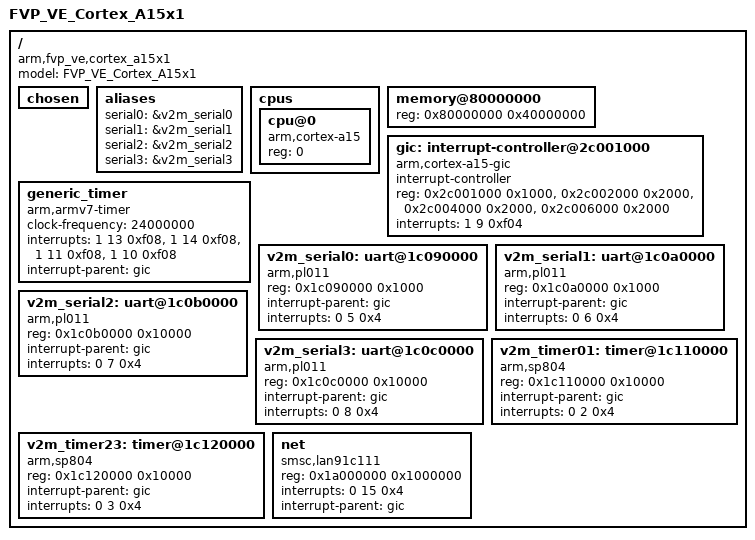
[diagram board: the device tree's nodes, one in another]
/*
 * ARM Ltd. Fast Models
 *
 * Versatile Express (VE) system model
 * ARMCortexA15x1CT
 *
 * RTSM_VE_Cortex_A15x1.lisa
 */

/dts-v1/;

/ {
	model = "FVP_VE_Cortex_A15x1";
	compatible = "arm,fvp_ve,cortex_a15x1";
	#address-cells = <1>;
	#size-cells = <1>;

	chosen { };

	aliases {
		serial0 = &v2m_serial0;
		serial1 = &v2m_serial1;
		serial2 = &v2m_serial2;
		serial3 = &v2m_serial3;
	};

	cpus {
		#address-cells = <1>;
		#size-cells = <0>;

		cpu@0 {
			device_type = "cpu";
			compatible = "arm,cortex-a15";
			reg = <0>;
		};
	};

	memory@80000000 {
		device_type = "memory";
		reg = <0x80000000 0x40000000>;
	};

	gic: interrupt-controller@2c001000 {
		compatible = "arm,cortex-a15-gic";
		interrupt-controller;
		#interrupt-cells = <3>;
		reg = <0x2c001000 0x1000>,
		      <0x2c002000 0x2000>,
		      <0x2c004000 0x2000>,
		      <0x2c006000 0x2000>;
		interrupts = <1 9 0xf04>;
	};
	generic_timer {
		compatible = "arm,armv7-timer";
		clock-frequency = <24000000>;
		interrupts = <1 13 0xf08>,
			     <1 14 0xf08>,
			     <1 11 0xf08>,
			     <1 10 0xf08>;
		interrupt-parent = <&gic>;
		};

	v2m_serial0: uart@1c090000 {
		compatible = "arm,pl011", "arm,primecell";
		reg = <0x1c090000 0x1000>;
		interrupt-parent=<&gic>;
		interrupts = <0 5 0x4>;
	};

	v2m_serial1: uart@1c0a0000 {
		compatible = "arm,pl011", "arm,primecell";
		reg = <0x1c0a0000 0x1000>;
		interrupt-parent=<&gic>;
		interrupts = <0 6 0x4>;
	};

	v2m_serial2: uart@1c0b0000 {
		compatible = "arm,pl011", "arm,primecell";
		reg = <0x1c0b0000 0x10000>;
		interrupt-parent=<&gic>;
		interrupts = <0 7 0x4>;
	};

	v2m_serial3: uart@1c0c0000 {
		compatible = "arm,pl011", "arm,primecell";
		reg = <0x1c0c0000 0x10000>;
		interrupt-parent=<&gic>;
		interrupts = <0 8 0x4>;
	};
	v2m_timer01: timer@1c110000 {
		compatible = "arm,sp804", "arm,primecell";
		reg = <0x1c110000 0x10000>;
		interrupt-parent=<&gic>;
		interrupts = <0 2 0x4>;
	};

	v2m_timer23: timer@1c120000 {
		compatible = "arm,sp804", "arm,primecell";
		reg = <0x1c120000 0x10000>;
		interrupt-parent=<&gic>;
		interrupts = <0 3 0x4>;
	};

	net {
		compatible = "smsc,lan91c111";
		reg = <0x1a000000 0x1000000>;
		interrupts = <0 15 0x4>;
		interrupt-parent = <&gic>;
	};
};

